AUTOSAR XML (schema 00048)
package /ProcessDesign
  process design qt_ota_client: executable=qt_ota_client
package /AdaptiveApplicationSwComponents
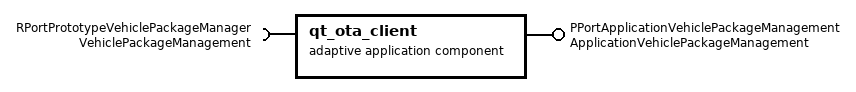
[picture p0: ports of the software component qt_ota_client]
  adaptive application sw component type qt_ota_client: category=APPLICATION_LEVEL
    require port RPortPrototypeVehiclePackageManager: required-interface=VehiclePackageManagement
    provide port PPortApplicationVehiclePackageManagement: provided-interface=ApplicationVehiclePackageManagement
package /Executables
  executable qt_ota_client
    root sw component prototype qt_ota_client_root: application-type=qt_ota_client
package /Processes
  process qt_ota_client: design=qt_ota_client, executable=qt_ota_client, state-dependent-startup-config{function-group-state=UcmMasterApplicationStates.Ucm_Master_Application1, resource-group=ResourceGroup, startup-config=qt_ota_client}
